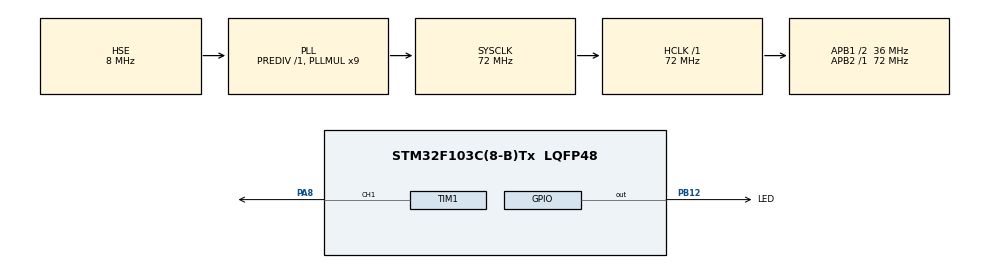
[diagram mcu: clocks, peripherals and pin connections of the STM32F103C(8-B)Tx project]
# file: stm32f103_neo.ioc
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Dma.Request0=TIM1_CH1
Dma.TIM1_CH1.0.Direction=DMA_MEMORY_TO_PERIPH
Dma.TIM1_CH1.0.Instance=DMA1_Channel2
Dma.TIM1_CH1.0.MemDataAlignment=DMA_MDATAALIGN_BYTE
Dma.TIM1_CH1.0.MemInc=DMA_MINC_ENABLE
Dma.TIM1_CH1.0.Mode=DMA_CIRCULAR
Dma.TIM1_CH1.0.PeriphDataAlignment=DMA_PDATAALIGN_HALFWORD
Dma.TIM1_CH1.0.PeriphInc=DMA_PINC_DISABLE
Dma.TIM1_CH1.0.Priority=DMA_PRIORITY_LOW
Mcu.Family=STM32F1
Mcu.Name=STM32F103C(8-B)Tx
Mcu.Package=LQFP48
NVIC.DMA1_Channel2_IRQn=true\:0\:0\:false\:false\:true\:false\:true
NVIC.PriorityGroup=NVIC_PRIORITYGROUP_4
PA13.Mode=Serial_Wire
PA13.Signal=SYS_JTMS-SWDIO
PA14.Mode=Serial_Wire
PA14.Signal=SYS_JTCK-SWCLK
PA8.Signal=S_TIM1_CH1
PB12.GPIO_Label=LED
PB12.Signal=GPIO_Output
PD0-OSC_IN.Mode=HSE-External-Oscillator
PD0-OSC_IN.Signal=RCC_OSC_IN
PD1-OSC_OUT.Mode=HSE-External-Oscillator
PD1-OSC_OUT.Signal=RCC_OSC_OUT
ProjectManager.HeapSize=0x200
ProjectManager.StackSize=0x400
ProjectManager.TargetToolchain=STM32CubeIDE
RCC.AHBFreq_Value=72000000
RCC.APB1CLKDivider=RCC_HCLK_DIV2
RCC.APB1Freq_Value=36000000
RCC.APB1TimFreq_Value=72000000
RCC.APB2Freq_Value=72000000
RCC.APB2TimFreq_Value=72000000
RCC.HCLKFreq_Value=72000000
RCC.PLLMUL=RCC_PLL_MUL9
RCC.PLLSourceVirtual=RCC_PLLSOURCE_HSE
RCC.SYSCLKFreq_VALUE=72000000
RCC.SYSCLKSource=RCC_SYSCLKSOURCE_PLLCLK
RCC.USBFreq_Value=72000000
SH.S_TIM1_CH1.0=TIM1_CH1,PWM Generation1 CH1
TIM1.Channel-PWM\ Generation1\ CH1=TIM_CHANNEL_1
TIM1.Period=90
TIM1.Pulse-PWM\ Generation1\ CH1=45
VP_TIM1_VS_ClockSourceINT.Mode=Internal
board=custom

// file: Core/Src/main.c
/* USER CODE BEGIN Header */
/**
  ******************************************************************************
  * @file           : main.c
  * @brief          : Main program body
  ******************************************************************************
  * @attention
  *
  * <h2><center>&copy; Copyright (c) 2021 STMicroelectronics.
  * All rights reserved.</center></h2>
  *
  * This software component is licensed by ST under BSD 3-Clause license,
  * the "License"; You may not use this file except in compliance with the
  * License. You may obtain a copy of the License at:
  *                        opensource.org/licenses/BSD-3-Clause
  *
  ******************************************************************************
  */
/* USER CODE END Header */
#include "main.h"
#include "dma.h"
#include "tim.h"
#include "gpio.h"

void SystemClock_Config(void);

/* USER CODE BEGIN 0 */

#define NEO_LED_CNT   8
#define BIT_WIDTH     32
#define BIT_OFFSET    66
#define BIT_LOW       25
#define BIT_HIGH      47

uint8_t neo_data[BIT_OFFSET + BIT_WIDTH*NEO_LED_CNT];

void neoSetPixel(uint8_t ch, uint8_t r, uint8_t g, uint8_t b)
{
  uint8_t r_bit[8];
  uint8_t g_bit[8];
  uint8_t b_bit[8];
  uint8_t w_bit[8];

  for (int i=0; i<8; i++)
  {
    if (r & (1<<7)) r_bit[i] = BIT_HIGH;
    else            r_bit[i] = BIT_LOW;
    r <<= 1;

    if (g & (1<<7)) g_bit[i] = BIT_HIGH;
    else            g_bit[i] = BIT_LOW;
    g <<= 1;

    if (b & (1<<7)) b_bit[i] = BIT_HIGH;
    else            b_bit[i] = BIT_LOW;
    b <<= 1;

    w_bit[i] = BIT_LOW;

    neo_data[BIT_OFFSET + BIT_WIDTH*ch + 8*0 + i] = g_bit[i];
    neo_data[BIT_OFFSET + BIT_WIDTH*ch + 8*1 + i] = r_bit[i];
    neo_data[BIT_OFFSET + BIT_WIDTH*ch + 8*2 + i] = b_bit[i];
    neo_data[BIT_OFFSET + BIT_WIDTH*ch + 8*3 + i] = w_bit[i];
  }
}

/* USER CODE END 0 */

int main(void)
{

  /* MCU Configuration--------------------------------------------------------*/

  /* Reset of all peripherals, Initializes the Flash interface and the Systick. */
  HAL_Init();

  /* Configure the system clock */
  SystemClock_Config();

  /* Initialize all configured peripherals */
  MX_GPIO_Init();
  MX_DMA_Init();
  MX_TIM1_Init();
  /* USER CODE BEGIN 2 */

  //HAL_TIM_PWM_Start(&htim1, TIM_CHANNEL_1);

  // 80us low
  for (int i=0; i<BIT_OFFSET; i++)
  {
    neo_data[i] = 0;
  }

  for (int i=0; i<NEO_LED_CNT; i++)
  {
    for (int j=0; j<BIT_WIDTH; j++)
    {
      neo_data[BIT_OFFSET + BIT_WIDTH*i + j] = BIT_LOW;
    }
  }

  HAL_TIM_PWM_Start_DMA(&htim1, TIM_CHANNEL_1, (uint32_t *)neo_data, BIT_OFFSET + BIT_WIDTH*NEO_LED_CNT);

  for (int i=0; i<NEO_LED_CNT; i++)
  {
    neoSetPixel(i, 0, 0, 50);
  }

  uint32_t led_index = 0;
  uint32_t led_color = 0;
  uint32_t pre_time;
  /* USER CODE END 2 */

  /* Infinite loop */
  while (1)
  {

    /* USER CODE BEGIN 3 */

    if (HAL_GetTick()-pre_time >= 100)
    {
      pre_time = HAL_GetTick();

      for (int i=0; i<NEO_LED_CNT; i++)
      {
        if (i == led_index)
        {
          switch(led_color)
          {
            case 0:
              neoSetPixel(i, 50, 0, 0);
              break;
            case 1:
              neoSetPixel(i,  0, 50, 0);
              break;
            case 2:
              neoSetPixel(i, 0, 0, 50);
              break;
          }
        }
        else
        {
          neoSetPixel(i, 0, 0, 0);
        }
      }

      led_index = (led_index + 1)%8;

      if (led_index == 0)
      {
        led_color = (led_color + 1)%3;
      }
    }
  }
  /* USER CODE END 3 */
}

void SystemClock_Config(void)
{
  RCC_OscInitTypeDef RCC_OscInitStruct = {0};
  RCC_ClkInitTypeDef RCC_ClkInitStruct = {0};

  /** Initializes the RCC Oscillators according to the specified parameters
  * in the RCC_OscInitTypeDef structure.
  */
  RCC_OscInitStruct.OscillatorType = RCC_OSCILLATORTYPE_HSE;
  RCC_OscInitStruct.HSEState = RCC_HSE_ON;
  RCC_OscInitStruct.HSEPredivValue = RCC_HSE_PREDIV_DIV1;
  RCC_OscInitStruct.HSIState = RCC_HSI_ON;
  RCC_OscInitStruct.PLL.PLLState = RCC_PLL_ON;
  RCC_OscInitStruct.PLL.PLLSource = RCC_PLLSOURCE_HSE;
  RCC_OscInitStruct.PLL.PLLMUL = RCC_PLL_MUL9;
  if (HAL_RCC_OscConfig(&RCC_OscInitStruct) != HAL_OK)
  {
    Error_Handler();
  }
  /** Initializes the CPU, AHB and APB buses clocks
  */
  RCC_ClkInitStruct.ClockType = RCC_CLOCKTYPE_HCLK|RCC_CLOCKTYPE_SYSCLK
                              |RCC_CLOCKTYPE_PCLK1|RCC_CLOCKTYPE_PCLK2;
  RCC_ClkInitStruct.SYSCLKSource = RCC_SYSCLKSOURCE_PLLCLK;
  RCC_ClkInitStruct.AHBCLKDivider = RCC_SYSCLK_DIV1;
  RCC_ClkInitStruct.APB1CLKDivider = RCC_HCLK_DIV2;
  RCC_ClkInitStruct.APB2CLKDivider = RCC_HCLK_DIV1;

  if (HAL_RCC_ClockConfig(&RCC_ClkInitStruct, FLASH_LATENCY_2) != HAL_OK)
  {
    Error_Handler();
  }
}

void Error_Handler(void)
{
  __disable_irq();
  while (1)
  {
  }
}

/************************ (C) COPYRIGHT STMicroelectronics *****END OF FILE****/
